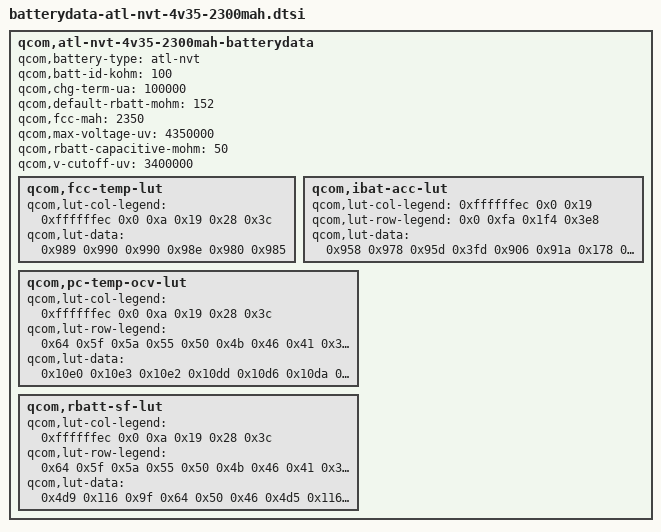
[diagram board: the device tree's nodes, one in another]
/* Copyright (c) 2018, The Linux Foundation. All rights reserved.
*
* This program is free software; you can redistribute it and/or modify
* it under the terms of the GNU General Public License version 2 and
* only version 2 as published by the Free Software Foundation.
*
* This program is distributed in the hope that it will be useful,
* but WITHOUT ANY WARRANTY; without even the implied warranty of
* MERCHANTABILITY or FITNESS FOR A PARTICULAR PURPOSE.  See the
* GNU General Public License for more details.
*/

qcom,atl-nvt-4v35-2300mah-batterydata {
	qcom,battery-type = "atl-nvt";
	qcom,batt-id-kohm = <100>;
	qcom,chg-term-ua = <100000>;
	qcom,default-rbatt-mohm = <152>;
	qcom,fcc-mah = <2350>;
	qcom,max-voltage-uv = <4350000>;
	qcom,rbatt-capacitive-mohm = <50>;
	qcom,v-cutoff-uv = <3400000>;

	qcom,fcc-temp-lut {
		qcom,lut-col-legend = <0xffffffec 0x0 0xa 0x19 0x28 0x3c>;
		qcom,lut-data = <0x989 0x990 0x990 0x98e 0x980 0x985>;
	};

	qcom,ibat-acc-lut {
		qcom,lut-col-legend = <0xffffffec 0x0 0x19>;
		qcom,lut-row-legend = <0x0 0xfa 0x1f4 0x3e8>;
		qcom,lut-data = <0x958 0x978 0x95d 0x3fd 0x906 0x91a 0x178 0x8fc 0x898 0x6 0x830 0x834>;
	};

	qcom,pc-temp-ocv-lut {
		qcom,lut-col-legend = <0xffffffec 0x0 0xa 0x19 0x28 0x3c>;
		qcom,lut-row-legend = <0x64 0x5f 0x5a 0x55 0x50 0x4b 0x46 0x41 0x3c 0x37 0x32 0x2d 0x28 0x23 0x1e 0x19 0x14 0x10 0xd 0xb 0xa 0x9 0x8 0x7 0x6 0x5 0x4 0x3 0x2 0x1 0x0>;
		qcom,lut-data = <0x10e0 0x10e3 0x10e2 0x10dd 0x10d6 0x10da 0x107c 0x1096 0x109a 0x1099 0x1095 0x1097 0x1038 0x105d 0x1061 0x1061 0x105d 0x105e 0x1000 0x1029 0x102d 0x102c 0x1028 0x1029 0xfcc 0xff8 0xffc 0xffa 0xff6 0xff6 0xf6c 0xfc5 0xfcf 0xfce 0xfc8 0xfc6 0xf48 0xf78 0xf8a 0xf92 0xf98 0xf9a 0xf23 0xf54 0xf66 0xf72 0xf73 0xf73 0xf02 0xf32 0xf3d 0xf49 0xf4a 0xf4b 0xeeb 0xf12 0xf18 0xf1c 0xf1e 0xf20 0xedc 0xef7 0xefc 0xefd 0xefd 0xefd 0xed1 0xee1 0xee6 0xee7 0xee7 0xee7 0xec6 0xed0 0xed4 0xed6 0xed6 0xed5 0xebc 0xec5 0xec7 0xec7 0xec7 0xec6 0xeb0 0xebc 0xebd 0xebb 0xeb7 0xeb2 0xea2 0xeb1 0xeb3 0xead 0xea5 0xe99 0xe92 0xea2 0xea3 0xe9c 0xe93 0xe85 0xe83 0xe8f 0xe90 0xe87 0xe7e 0xe71 0xe75 0xe7f 0xe7c 0xe72 0xe6a 0xe5d 0xe69 0xe76 0xe72 0xe6a 0xe62 0xe56 0xe61 0xe73 0xe6f 0xe69 0xe61 0xe55 0xe58 0xe70 0xe6e 0xe67 0xe60 0xe54 0xe4d 0xe6c 0xe6b 0xe66 0xe5e 0xe52 0xe3f 0xe68 0xe68 0xe63 0xe5b 0xe4f 0xe2d 0xe60 0xe63 0xe5a 0xe52 0xe43 0xe16 0xe4e 0xe50 0xe3f 0xe39 0xe26 0xdf4 0xe28 0xe25 0xe10 0xe0b 0xdf8 0xdc0 0xdf0 0xdec 0xdd1 0xdce 0xdbb 0xd6e 0xda3 0xda0 0xd7c 0xd7b 0xd68 0xcd3 0xd12 0xd16 0xcfd 0xd05 0xcec 0xbb8 0xbb8 0xbb8 0xc1c 0xbb8 0xbb8>;
	};

	qcom,rbatt-sf-lut {
		qcom,lut-col-legend = <0xffffffec 0x0 0xa 0x19 0x28 0x3c>;
		qcom,lut-row-legend = <0x64 0x5f 0x5a 0x55 0x50 0x4b 0x46 0x41 0x3c 0x37 0x32 0x2d 0x28 0x23 0x1e 0x19 0x14 0x10 0xd 0xb 0xa 0x9 0x8 0x7 0x6 0x5 0x4 0x3 0x2 0x1 0x0>;
		qcom,lut-data = <0x4d9 0x116 0x9f 0x64 0x50 0x46 0x4d5 0x116 0x9f 0x64 0x50 0x46 0x472 0x11c 0xa3 0x65 0x50 0x46 0x432 0x122 0xa8 0x68 0x52 0x47 0x415 0x124 0xae 0x6b 0x54 0x48 0x3be 0x132 0xba 0x72 0x57 0x4a 0x3bf 0x10c 0xb1 0x72 0x59 0x4c 0x3b9 0x108 0xaf 0x7a 0x5e 0x4f 0x3b5 0x101 0xa1 0x75 0x5f 0x50 0x3c3 0xfb 0x97 0x65 0x55 0x4b 0x3db 0xfa 0x94 0x5e 0x4e 0x46 0x401 0xfa 0x95 0x5f 0x4f 0x47 0x430 0xfc 0x95 0x61 0x51 0x49 0x468 0x103 0x97 0x62 0x53 0x4b 0x4a6 0x10d 0x9a 0x62 0x52 0x49 0x4ec 0x11d 0x9e 0x61 0x4e 0x46 0x53f 0x132 0xa2 0x61 0x4f 0x46 0x58b 0x147 0xa6 0x62 0x4f 0x46 0x596 0x14a 0xa4 0x61 0x4e 0x46 0x5d3 0x160 0xa8 0x61 0x4d 0x46 0x5f1 0x170 0xab 0x62 0x4f 0x47 0x610 0x185 0xb1 0x64 0x51 0x48 0x62d 0x199 0xb6 0x67 0x53 0x49 0x64e 0x1b8 0xbf 0x6a 0x54 0x4b 0x674 0x1d3 0xc9 0x6d 0x55 0x4a 0x6ea 0x1f0 0xd0 0x6a 0x53 0x48 0x7db 0x212 0xd3 0x6b 0x53 0x49 0x959 0x251 0xe8 0x6f 0x56 0x4c 0xc7b 0x2b3 0x106 0x7b 0x5d 0x52 0x1868 0x7f2 0x2ae 0x99 0x93 0x71 0x1868 0x7f2 0x2ae 0x99 0x93 0x71>;
	};
};

